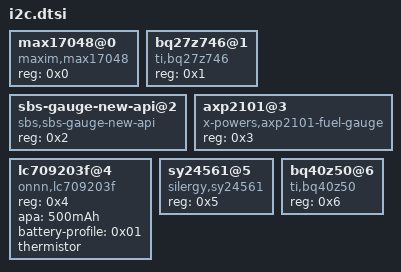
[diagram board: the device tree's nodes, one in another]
/*
 * Copyright (c) 2024 TOKITA Hiroshi
 * SPDX-License-Identifier: Apache-2.0
 */

/****************************************
 * PLEASE KEEP REG ADDRESSES SEQUENTIAL *
 **************************************
 */

max17048@0 {
	compatible = "maxim,max17048";
	reg = <0x0>;
	status = "okay";
};

bq27z746@1 {
	compatible = "ti,bq27z746";
	reg = <0x1>;
	status = "okay";
};

sbs-gauge-new-api@2 {
	compatible = "sbs,sbs-gauge-new-api";
	reg = <0x2>;
	status = "okay";
};

axp2101@3 {
	compatible = "x-powers,axp2101-fuel-gauge";
	reg = <0x3>;
	status = "okay";
};

lc709203f@4 {
	compatible = "onnn,lc709203f";
	reg = <0x4>;
	status = "okay";
	apa = "500mAh";
	battery-profile = <0x01>;
	thermistor;
};

sy24561@5 {
	compatible = "silergy,sy24561";
	reg = <0x5>;
	status = "okay";
};

bq40z50@6 {
	compatible = "ti,bq40z50";
	reg = <0x6>;
	status = "okay";
};
